# PIC32CX1025SG60128 device description
Architecture: CORTEX-M4; Family: PIC32CX; Series: PIC32CXSG60
Registers are 32-bit, read-write, reset 0x0 unless marked. A register's access mark holds for its fields unless they carry their own. Offsets are from the block's base; [hi:lo] are bit positions; {n}, {i} and the like mark numbered series; 'fields as' and 'values as' point back to an identical list; <NAME> marks a mode.

## DAC — Digital-to-Analog Converter
Instances: DAC 0x43002400
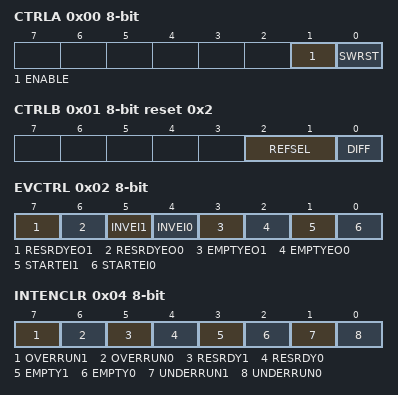
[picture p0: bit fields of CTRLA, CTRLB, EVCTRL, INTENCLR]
0x00 CTRLA 8-bit (WSYNC) — Control A
  [1] ENABLE — Enable DAC Controller
  [0] SWRST — Software Reset
0x01 CTRLB 8-bit reset 0x2 — Control B
  [2:1] REFSEL — Reference Selection for DAC0/1
    0=VREFAU (External reference unbuffered); 1=AVDD (Analog supply); 2=VREFAB (External reference buffered); 3=INTREF (Internal bandgap reference)
  [0] DIFF — Differential mode enable
0x02 EVCTRL 8-bit — Event Control
  [7] RESRDYEO1 — Result Ready Event Output 1
  [6] RESRDYEO0 — Result Ready Event Output 0
  [5] INVEI1 — Enable Invertion of DAC 1 input event
  [4] INVEI0 — Enable Invertion of DAC 0 input event
  [3] EMPTYEO1 — Data Buffer Empty Event Output DAC 1
  [2] EMPTYEO0 — Data Buffer Empty Event Output DAC 0
  [1] STARTEI1 — Start Conversion Event Input DAC 1
  [0] STARTEI0 — Start Conversion Event Input DAC 0
0x04 INTENCLR 8-bit (atomic clear) — Interrupt Enable Clear
  [7] OVERRUN1 — Overrun 1 Interrupt Enable
  [6] OVERRUN0 — Overrun 0 Interrupt Enable
  [5] RESRDY1 — Result 1 Ready Interrupt Enable
  [4] RESRDY0 — Result 0 Ready Interrupt Enable
  [3] EMPTY1 — Data Buffer 1 Empty Interrupt Enable
  [2] EMPTY0 — Data Buffer 0 Empty Interrupt Enable
  [1] UNDERRUN1 — Underrun 1 Interrupt Enable
  [0] UNDERRUN0 — Underrun 0 Interrupt Enable
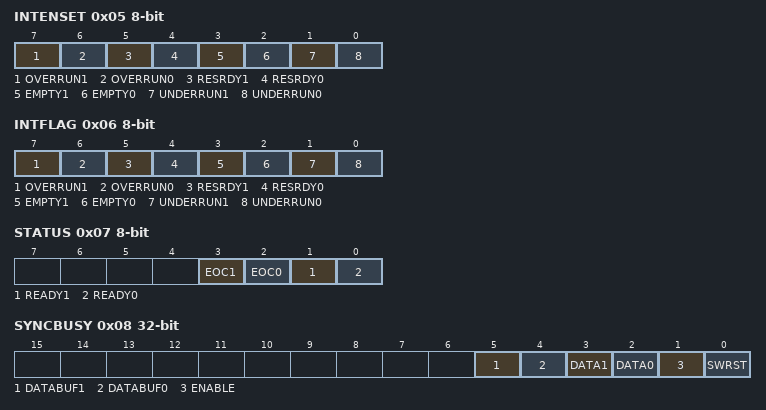
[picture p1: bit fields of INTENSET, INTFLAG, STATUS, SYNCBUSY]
0x05 INTENSET 8-bit (atomic set) — Interrupt Enable Set
  fields as INTENCLR
0x06 INTFLAG 8-bit (atomic clear) — Interrupt Flag Status and Clear
  [7] OVERRUN1 — Result 1 Overrun
  [6] OVERRUN0 — Result 0 Overrun
  [5] RESRDY1 — Result 1 Ready
  [4] RESRDY0 — Result 0 Ready
  [3] EMPTY1 — Data Buffer 1 Empty
  [2] EMPTY0 — Data Buffer 0 Empty
  [1] UNDERRUN1 — Result 1 Underrun
  [0] UNDERRUN0 — Result 0 Underrun
0x07 STATUS 8-bit ro
  [3] EOC1 — DAC 1 End of Conversion
  [2] EOC0 — DAC 0 End of Conversion
  [1] READY1 — DAC 1 Startup Ready
  [0] READY0 — DAC 0 Startup Ready
0x08 SYNCBUSY ro — Synchronization Busy
  [5] DATABUF1 — Data Buffer DAC 1
  [4] DATABUF0 — Data Buffer DAC 0
  [3] DATA1 — Data DAC 1
  [2] DATA0 — Data DAC 0
  [1] ENABLE — DAC Enable Status
  [0] SWRST — Software Reset
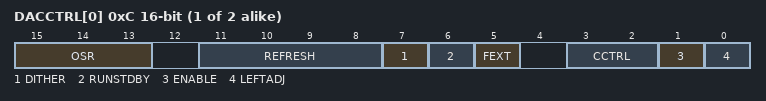
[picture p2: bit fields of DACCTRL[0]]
{0xC+2i} DACCTRL[{i}] (i=0..1) 16-bit — DAC n Control
  [15:13] OSR — Sampling Rate
    0=No Over Sampling; 1=2x Over Sampling Ratio; 2=4x Over Sampling Ratio; 3=8x Over Sampling Ratio; 4=16x Over Sampling Ratio; 5=32x Over Sampling Ratio
  [11:8] REFRESH — Refresh period
    0=Do not Refresh; 1=Refresh every 30 us; 2=Refresh every 60 us; 3=Refresh every 90 us; 4=Refresh every 120 us; 5=Refresh every 150 us; 6=Refresh every 180 us; 7=Refresh every 210 us; 8=Refresh every 240 us; 9=Refresh every 270 us; 10=Refresh every 300 us; 11=Refresh every 330 us; 12=Refresh every 360 us; 13=Refresh every 390 us; 14=Refresh every 420 us; 15=Refresh every 450 us
  [7] DITHER — Dithering Mode
  [6] RUNSTDBY — Run in Standby
  [5] FEXT — Standalone Filter
  [3:2] CCTRL — Current Control
    0=CC100K (100kSPS); 1=CC1M (500kSPS); 2=CC12M (1MSPS)
  [1] ENABLE — Enable DAC0
  [0] LEFTADJ — Left Adjusted Data
{0x10+2i} DATA[{i}] (i=0..1) 16-bit wo (WSYNC) — DAC n Data
  [15:0] DATA — DAC0 Data
{0x14+2i} DATABUF[{i}] (i=0..1) 16-bit wo (WSYNC) — DAC n Data Buffer
  [15:0] DATABUF — DAC0 Data Buffer
0x18 DBGCTRL 8-bit — Debug Control
  [0] DBGRUN — Debug Run
{0x1C+2i} RESULT[{i}] (i=0..1) 16-bit ro — Filter Result

## DMAC_DESCRIPTOR — Direct Memory Access Controller
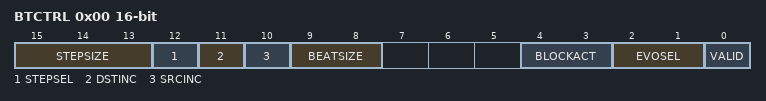
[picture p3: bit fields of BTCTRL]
0x00 BTCTRL 16-bit — Block Transfer Control
  [15:13] STEPSIZE — Address Increment Step Size
    0=Next ADDR = ADDR + (1<<BEATSIZE) * 1; 1=X2 (Next ADDR = ADDR + (1<<BEATSIZE) * 2); 2=X4 (Next ADDR = ADDR + (1<<BEATSIZE) * 4); 3=X8 (Next ADDR = ADDR + (1<<BEATSIZE) * 8); 4=X16 (Next ADDR = ADDR + (1<<BEATSIZE) * 16); 5=X32 (Next ADDR = ADDR + (1<<BEATSIZE) * 32); 6=X64 (Next ADDR = ADDR + (1<<BEATSIZE) * 64); 7=X128 (Next ADDR = ADDR + (1<<BEATSIZE) * 128)
  [12] STEPSEL — Step Selection
    0=DST (Step size settings apply to the destination address); 1=SRC (Step size settings apply to the source address)
  [11] DSTINC — Destination Address Increment Enable
  [10] SRCINC — Source Address Increment Enable
  [9:8] BEATSIZE
    0=BYTE (8-bit bus transfer); 1=HWORD (16-bit bus transfer); 2=WORD (32-bit bus transfer)
  [4:3] BLOCKACT — Block Action
    0=NOACT (Channel will be disabled if it is the last block transfer in the transaction); 1=INT (Channel will be disabled if it is the last block transfer in the transaction and block interrupt); 2=SUSPEND (Channel suspend operation is completed); 3=BOTH (Both channel suspend operation and block interrupt)
  [2:1] EVOSEL — Block Event Output Selection
    0=DISABLE (Event generation disabled); 1=BLOCK (Block event strobe); 3=BURST (Burst event strobe)
  [0] VALID — Descriptor Valid
0x02 BTCNT 16-bit — Block Transfer Count
0x04 SRCADDR — Block Transfer Source Address
  [31:0] SRCADDR — Transfer Source Address
0x08 DSTADDR reset not defined — Block Transfer Destination Address
  [31:0] CHKINIT <CRC> — CRC Checksum Initial Value
  [31:0] DSTADDR <DEFAULT> — Transfer Destination Address
0x0C DESCADDR reset not defined — Next Descriptor Address

## Notices in the file
Copyright (c) 2021 Microchip Technology Inc.
SPDX-License-Identifier: Apache-2.0
Licensed under the Apache License, Version 2.0 (the "License");
you may not use this file except in compliance with the License.
You may obtain a copy of the License at
http://www.apache.org/licenses/LICENSE-2.0
Unless required by applicable law or agreed to in writing, software
distributed under the License is distributed on an "AS IS" BASIS,
WITHOUT WARRANTIES OR CONDITIONS OF ANY KIND, either express or implied.
See the License for the specific language governing permissions and
limitations under the License.
